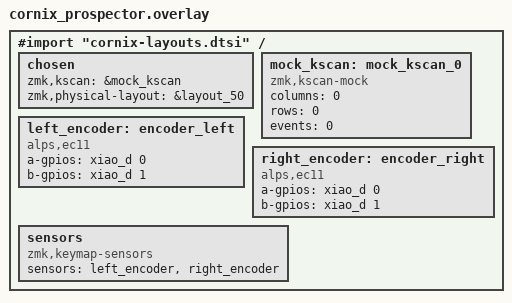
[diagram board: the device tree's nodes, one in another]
#include <dt-bindings/zmk/matrix_transform.h>
#import "cornix-layouts.dtsi"

/ {
    chosen {
        zmk,kscan = &mock_kscan;
        zmk,physical-layout = &layout_50;
    };

    mock_kscan: mock_kscan_0 {
        compatible = "zmk,kscan-mock";
        columns = <0>;
        rows = <0>;
        events = <0>;
    };

    // ダミーのエンコーダー定義(実際には物理的に存在しないが、
    // centralとしてロータリー操作を正しく処理させるために必要)
    left_encoder: encoder_left {
        compatible = "alps,ec11";
        a-gpios = <&xiao_d 0 GPIO_ACTIVE_HIGH>;
        b-gpios = <&xiao_d 1 GPIO_ACTIVE_HIGH>;
        status = "okay";
    };

    right_encoder: encoder_right {
        compatible = "alps,ec11";
        a-gpios = <&xiao_d 0 GPIO_ACTIVE_HIGH>;
        b-gpios = <&xiao_d 1 GPIO_ACTIVE_HIGH>;
        status = "okay";
    };

    sensors: sensors {
        compatible = "zmk,keymap-sensors";
        sensors = <&left_encoder &right_encoder>;
    };
};
